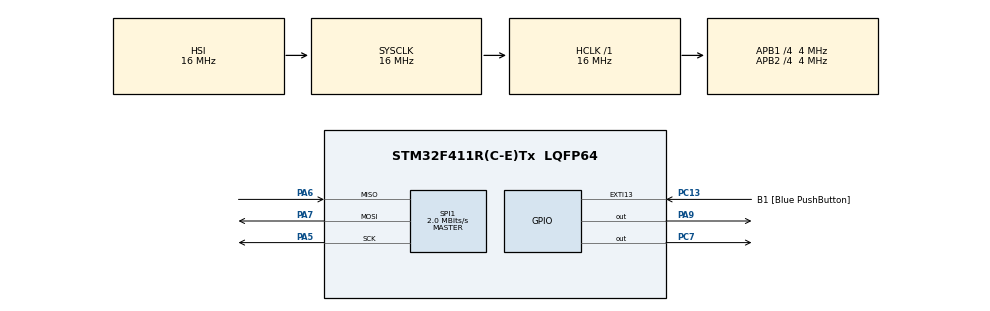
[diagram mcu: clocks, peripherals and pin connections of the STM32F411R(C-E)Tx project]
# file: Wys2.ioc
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Mcu.Family=STM32F4
Mcu.Name=STM32F411R(C-E)Tx
Mcu.Package=LQFP64
NVIC.PriorityGroup=NVIC_PRIORITYGROUP_0
PA13.GPIO_Label=TMS
PA13.Signal=SYS_JTMS-SWDIO
PA14.GPIO_Label=TCK
PA14.Signal=SYS_JTCK-SWCLK
PA2.GPIO_Label=USART_TX
PA2.Signal=USART2_TX
PA3.GPIO_Label=USART_RX
PA3.Signal=USART2_RX
PA5.Mode=Full_Duplex_Master
PA5.Signal=SPI1_SCK
PA6.Mode=Full_Duplex_Master
PA6.Signal=SPI1_MISO
PA7.Mode=Full_Duplex_Master
PA7.Signal=SPI1_MOSI
PA9.Signal=GPIO_Output
PB3.GPIO_Label=SWO
PB3.Signal=SYS_JTDO-SWO
PC13-ANTI_TAMP.GPIO_Label=B1 [Blue PushButton]
PC13-ANTI_TAMP.GPIO_ModeDefaultEXTI=GPIO_MODE_IT_FALLING
PC13-ANTI_TAMP.Signal=GPXTI13
PC14-OSC32_IN.Signal=RCC_OSC32_IN
PC15-OSC32_OUT.Signal=RCC_OSC32_OUT
PC7.Signal=GPIO_Output
PH0\ -\ OSC_IN.Signal=RCC_OSC_IN
PH1\ -\ OSC_OUT.Signal=RCC_OSC_OUT
ProjectManager.HeapSize=0x200
ProjectManager.StackSize=0x400
ProjectManager.TargetToolchain=MDK-ARM V5
RCC.48MHZClocksFreq_Value=84000000
RCC.AHBFreq_Value=16000000
RCC.APB1CLKDivider=RCC_HCLK_DIV4
RCC.APB1Freq_Value=4000000
RCC.APB1TimFreq_Value=8000000
RCC.APB2CLKDivider=RCC_HCLK_DIV4
RCC.APB2Freq_Value=4000000
RCC.APB2TimFreq_Value=8000000
RCC.CortexFreq_Value=16000000
RCC.FLatency-AdvancedSettings=FLASH_LATENCY_0
RCC.HCLKFreq_Value=16000000
RCC.HSE_VALUE=8000000
RCC.HSI_VALUE=16000000
RCC.LSE_VALUE=32768
RCC.PLLN=336
RCC.PLLP=RCC_PLLP_DIV4
RCC.SYSCLKFreq_VALUE=16000000
RCC.VCOOutputFreq_Value=336000000
SPI1.CalculateBaudRate=2.0 MBits/s
SPI1.Direction=SPI_DIRECTION_2LINES
SPI1.Mode=SPI_MODE_MASTER
SPI1.VirtualType=VM_MASTER
board=NUCLEO-F411RE

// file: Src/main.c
/**
  ******************************************************************************
  * @file           : main.c
  * @brief          : Main program body
  ******************************************************************************
  ** This notice applies to any and all portions of this file
  * that are not between comment pairs USER CODE BEGIN and
  * USER CODE END. Other portions of this file, whether
  * inserted by the user or by software development tools
  * are owned by their respective copyright owners.
  *
  * COPYRIGHT(c) 2018 STMicroelectronics
  *
  * Redistribution and use in source and binary forms, with or without modification,
  * are permitted provided that the following conditions are met:
  *   1. Redistributions of source code must retain the above copyright notice,
  *      this list of conditions and the following disclaimer.
  *   2. Redistributions in binary form must reproduce the above copyright notice,
  *      this list of conditions and the following disclaimer in the documentation
  *      and/or other materials provided with the distribution.
  *   3. Neither the name of STMicroelectronics nor the names of its contributors
  *      may be used to endorse or promote products derived from this software
  *      without specific prior written permission.
  *
  * THIS SOFTWARE IS PROVIDED BY THE COPYRIGHT HOLDERS AND CONTRIBUTORS "AS IS"
  * AND ANY EXPRESS OR IMPLIED WARRANTIES, INCLUDING, BUT NOT LIMITED TO, THE
  * IMPLIED WARRANTIES OF MERCHANTABILITY AND FITNESS FOR A PARTICULAR PURPOSE ARE
  * DISCLAIMED. IN NO EVENT SHALL THE COPYRIGHT HOLDER OR CONTRIBUTORS BE LIABLE
  * FOR ANY DIRECT, INDIRECT, INCIDENTAL, SPECIAL, EXEMPLARY, OR CONSEQUENTIAL
  * DAMAGES (INCLUDING, BUT NOT LIMITED TO, PROCUREMENT OF SUBSTITUTE GOODS OR
  * SERVICES; LOSS OF USE, DATA, OR PROFITS; OR BUSINESS INTERRUPTION) HOWEVER
  * CAUSED AND ON ANY THEORY OF LIABILITY, WHETHER IN CONTRACT, STRICT LIABILITY,
  * OR TORT (INCLUDING NEGLIGENCE OR OTHERWISE) ARISING IN ANY WAY OUT OF THE USE
  * OF THIS SOFTWARE, EVEN IF ADVISED OF THE POSSIBILITY OF SUCH DAMAGE.
  *
  ******************************************************************************
  */
#include "main.h"
#include "stm32f4xx_hal.h"

#include <math.h>
#include <stdarg.h>

#define ILOSC_WYSWIETLACZY 7

SPI_HandleTypeDef hspi1;

/* USER CODE BEGIN PV */
/* Private variables ---------------------------------------------------------*/

/* USER CODE END PV */

void SystemClock_Config(void);
static void MX_GPIO_Init(void);
static void MX_SPI1_Init(void);

/* USER CODE BEGIN PFP */
/* Private function prototypes -----------------------------------------------*/

/* USER CODE END PFP */

/* USER CODE BEGIN 0 */
uint8_t dane[2] = {0, 0};
uint8_t cyfryLiczby[ILOSC_WYSWIETLACZY] = {0};
uint16_t popliczba = 0;

/* USER CODE END 0 */
//const uint8_t wyswietlacz = {}

const uint8_t cyfry[10] = {
													 0x80 + 0x40 + 0x20 + 0x10 + 0x08 + 0x04,
													 0x40 + 0x20,
													 0x80 + 0x40 + 0x02 + 0x08 + 0x10,
													 0x80 + 0x40 + 0x02 + 0x20 + 0x10,
													 0x04 + 0x02 + 0x20 + 0x40,
													 0x80 + 0x04 + 0x02 + 0x20 + 0x10,
													 0x80 + 0x04 + 0x02 + 0x08 + 0x10 + 0x20,
													 0x80 + 0x40 + 0x20,
													 0x80 + 0x40 + 0x20 + 0x10 + 0x08+ 0x04 + 0x02,
													 0x80 + 0x40 + 0x02 + 0x04 + 0x20 + 0x10
													};

inline uint8_t MaskaWyswietlacza(uint8_t wys)
{
	return 1 << (wys + 1);
}

uint8_t WyswietlaczeMaska(int n_args, ...){
				uint8_t result = 0;
        va_list ap;
        int i;
        va_start(ap, n_args);
        for(i=0; i < n_args; ++i)
              result |= MaskaWyswietlacza((uint8_t)va_arg(ap, int));
        va_end(ap);
				return result;
}

uint8_t* Wyswietl(uint8_t maskaWyswietlacza, uint8_t cyfra, uint8_t kropka)
{
		dane[0] = maskaWyswietlacza;
		dane[0] |= (cyfry[cyfra]>>7);
		dane[1] = (cyfry[cyfra]<<1) | (kropka ? 2 : 0);
		return dane;
}

void Wygas()
{
		uint8_t dane[2] = {0, 0};
		HAL_SPI_Transmit(&hspi1, (uint8_t*)dane, 2, HAL_MAX_DELAY);
		while(HAL_SPI_GetState(&hspi1) != HAL_SPI_STATE_READY);
		HAL_SPI_Transmit(&hspi1, (uint8_t*)dane, 2, HAL_MAX_DELAY);
}

void WyslijDaneDoWyswietlacza()
{
		Wygas();
		//HAL_GPIO_WritePin(GPIOC, GPIO_PIN_7, GPIO_PIN_SET);
		HAL_SPI_Transmit(&hspi1, (uint8_t*)dane, 2, HAL_MAX_DELAY);
		while(HAL_SPI_GetState(&hspi1) != HAL_SPI_STATE_READY);
		HAL_SPI_Transmit(&hspi1, (uint8_t*)dane, 2, HAL_MAX_DELAY);
		//HAL_GPIO_WritePin(GPIOC, GPIO_PIN_7, GPIO_PIN_RESET);
		HAL_Delay(1);
}

void KonwertujLiczbeNaCyfry(uint32_t liczba)
{
		uint8_t i = 0;
		for (i; i < ILOSC_WYSWIETLACZY - 1; ++i)
			cyfryLiczby[i] = liczba / (int)pow(10, ILOSC_WYSWIETLACZY - i - 1) % 10;
		cyfryLiczby[ILOSC_WYSWIETLACZY - 1] = liczba % 10;
}

void PrzesunCyfry(uint8_t offset)
{
	uint8_t i = 0;
	for (i; i < ILOSC_WYSWIETLACZY - 1; ++i)
		cyfryLiczby[i] = cyfryLiczby[i + offset];
}

uint8_t KonwertujPrzyciskNaLiczbe(uint16_t liczba)
{
	uint8_t i = 0;
	for (;i<16;++i)
		if ((~liczba & (1<<i))) return i+1;
	return 0;
}

int main(void)
{

  /* MCU Configuration----------------------------------------------------------*/

  /* Reset of all peripherals, Initializes the Flash interface and the Systick. */
  HAL_Init();

  /* Configure the system clock */
  SystemClock_Config();

  /* Initialize all configured peripherals */
  MX_GPIO_Init();
  MX_SPI1_Init();

  /* Infinite loop */
  /* USER CODE BEGIN WHILE */

//	uint8_t dane[2] = {wyswietlacze(5, 0, 2, 3, 5, 6), 0x00};
//	dane[0] = dane[0] | (cyfry[0]>>7);
//	dane[1] = (cyfry[0]<<1);
//	Wyswietl(wyswietlacze(5, 0, 2, 4, 5, 6), 9, 0);
	//KonwertujLiczbeNaCyfry(891);
	int i = 0;
	uint8_t txData[2] = {0};
	uint8_t rxData[2];
  while (1)
  {
  /* USER CODE END WHILE */
		for (i = 0; i < ILOSC_WYSWIETLACZY; ++i)
		{
			Wyswietl(MaskaWyswietlacza(i), cyfryLiczby[i], 0);
			WyslijDaneDoWyswietlacza();
		}
		HAL_GPIO_WritePin(GPIOA, GPIO_PIN_9, GPIO_PIN_SET);
		HAL_SPI_TransmitReceive(&hspi1, txData, rxData, 2, 100);
		HAL_GPIO_WritePin(GPIOA, GPIO_PIN_9, GPIO_PIN_RESET);
		uint8_t nowaliczba = KonwertujPrzyciskNaLiczbe(rxData[0]<<8 | rxData[1]);
		if (popliczba != nowaliczba && nowaliczba != 0)
		{
			PrzesunCyfry(nowaliczba >= 10 ? 2 : 1);
			cyfryLiczby[6]=(KonwertujPrzyciskNaLiczbe(rxData[0]<<8 | rxData[1]));

			popliczba = nowaliczba;
		}
  }
}

void SystemClock_Config(void)
{

  RCC_OscInitTypeDef RCC_OscInitStruct;
  RCC_ClkInitTypeDef RCC_ClkInitStruct;

    /**Configure the main internal regulator output voltage
    */
  __HAL_RCC_PWR_CLK_ENABLE();

  __HAL_PWR_VOLTAGESCALING_CONFIG(PWR_REGULATOR_VOLTAGE_SCALE1);

    /**Initializes the CPU, AHB and APB busses clocks
    */
  RCC_OscInitStruct.OscillatorType = RCC_OSCILLATORTYPE_HSI;
  RCC_OscInitStruct.HSIState = RCC_HSI_ON;
  RCC_OscInitStruct.HSICalibrationValue = 16;
  RCC_OscInitStruct.PLL.PLLState = RCC_PLL_NONE;
  if (HAL_RCC_OscConfig(&RCC_OscInitStruct) != HAL_OK)
  {
    _Error_Handler(__FILE__, __LINE__);
  }

    /**Initializes the CPU, AHB and APB busses clocks
    */
  RCC_ClkInitStruct.ClockType = RCC_CLOCKTYPE_HCLK|RCC_CLOCKTYPE_SYSCLK
                              |RCC_CLOCKTYPE_PCLK1|RCC_CLOCKTYPE_PCLK2;
  RCC_ClkInitStruct.SYSCLKSource = RCC_SYSCLKSOURCE_HSI;
  RCC_ClkInitStruct.AHBCLKDivider = RCC_SYSCLK_DIV1;
  RCC_ClkInitStruct.APB1CLKDivider = RCC_HCLK_DIV4;
  RCC_ClkInitStruct.APB2CLKDivider = RCC_HCLK_DIV4;

  if (HAL_RCC_ClockConfig(&RCC_ClkInitStruct, FLASH_LATENCY_0) != HAL_OK)
  {
    _Error_Handler(__FILE__, __LINE__);
  }

    /**Configure the Systick interrupt time
    */
  HAL_SYSTICK_Config(HAL_RCC_GetHCLKFreq()/1000);

    /**Configure the Systick
    */
  HAL_SYSTICK_CLKSourceConfig(SYSTICK_CLKSOURCE_HCLK);

  /* SysTick_IRQn interrupt configuration */
  HAL_NVIC_SetPriority(SysTick_IRQn, 0, 0);
}

/* SPI1 init function */
static void MX_SPI1_Init(void)
{

  /* SPI1 parameter configuration*/
  hspi1.Instance = SPI1;
  hspi1.Init.Mode = SPI_MODE_MASTER;
  hspi1.Init.Direction = SPI_DIRECTION_2LINES;
  hspi1.Init.DataSize = SPI_DATASIZE_8BIT;
  hspi1.Init.CLKPolarity = SPI_POLARITY_LOW;
  hspi1.Init.CLKPhase = SPI_PHASE_1EDGE;
  hspi1.Init.NSS = SPI_NSS_SOFT;
  hspi1.Init.BaudRatePrescaler = SPI_BAUDRATEPRESCALER_2;
  hspi1.Init.FirstBit = SPI_FIRSTBIT_MSB;
  hspi1.Init.TIMode = SPI_TIMODE_DISABLE;
  hspi1.Init.CRCCalculation = SPI_CRCCALCULATION_DISABLE;
  hspi1.Init.CRCPolynomial = 10;
  if (HAL_SPI_Init(&hspi1) != HAL_OK)
  {
    _Error_Handler(__FILE__, __LINE__);
  }

}

/** Configure pins as
        * Analog
        * Input
        * Output
        * EVENT_OUT
        * EXTI
     PA2   ------> USART2_TX
     PA3   ------> USART2_RX
*/
static void MX_GPIO_Init(void)
{

  GPIO_InitTypeDef GPIO_InitStruct;

  /* GPIO Ports Clock Enable */
  __HAL_RCC_GPIOC_CLK_ENABLE();
  __HAL_RCC_GPIOH_CLK_ENABLE();
  __HAL_RCC_GPIOA_CLK_ENABLE();
  __HAL_RCC_GPIOB_CLK_ENABLE();

  /*Configure GPIO pin Output Level */
  HAL_GPIO_WritePin(GPIOC, GPIO_PIN_7, GPIO_PIN_RESET);

  /*Configure GPIO pin Output Level */
  HAL_GPIO_WritePin(GPIOA, GPIO_PIN_9, GPIO_PIN_RESET);

  /*Configure GPIO pin : B1_Pin */
  GPIO_InitStruct.Pin = B1_Pin;
  GPIO_InitStruct.Mode = GPIO_MODE_IT_FALLING;
  GPIO_InitStruct.Pull = GPIO_NOPULL;
  HAL_GPIO_Init(B1_GPIO_Port, &GPIO_InitStruct);

  /*Configure GPIO pins : USART_TX_Pin USART_RX_Pin */
  GPIO_InitStruct.Pin = USART_TX_Pin|USART_RX_Pin;
  GPIO_InitStruct.Mode = GPIO_MODE_AF_PP;
  GPIO_InitStruct.Pull = GPIO_NOPULL;
  GPIO_InitStruct.Speed = GPIO_SPEED_FREQ_VERY_HIGH;
  GPIO_InitStruct.Alternate = GPIO_AF7_USART2;
  HAL_GPIO_Init(GPIOA, &GPIO_InitStruct);

  /*Configure GPIO pin : PC7 */
  GPIO_InitStruct.Pin = GPIO_PIN_7;
  GPIO_InitStruct.Mode = GPIO_MODE_OUTPUT_PP;
  GPIO_InitStruct.Pull = GPIO_NOPULL;
  GPIO_InitStruct.Speed = GPIO_SPEED_FREQ_LOW;
  HAL_GPIO_Init(GPIOC, &GPIO_InitStruct);

  /*Configure GPIO pin : PA9 */
  GPIO_InitStruct.Pin = GPIO_PIN_9;
  GPIO_InitStruct.Mode = GPIO_MODE_OUTPUT_PP;
  GPIO_InitStruct.Pull = GPIO_NOPULL;
  GPIO_InitStruct.Speed = GPIO_SPEED_FREQ_LOW;
  HAL_GPIO_Init(GPIOA, &GPIO_InitStruct);

}

void _Error_Handler(char *file, int line)
{
  while(1)
  {
  }
}

/************************ (C) COPYRIGHT STMicroelectronics *****END OF FILE****/
